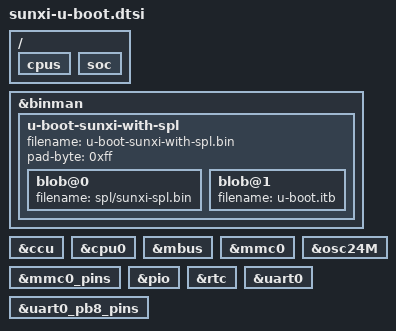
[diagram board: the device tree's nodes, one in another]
// SPDX-License-Identifier: (GPL-2.0 OR MIT)

#include "binman.dtsi"

/ {
	cpus {
		u-boot,dm-spl;
	};

	soc {
		u-boot,dm-spl;
	};
};

&binman {
	u-boot-sunxi-with-spl {
		filename = "u-boot-sunxi-with-spl.bin";
		pad-byte = <0xff>;

		blob@0 {
			filename = "spl/sunxi-spl.bin";
		};

		blob@1 {
			filename = "u-boot.itb";
		};
	};
};

&ccu {
	u-boot,dm-spl;
};

&cpu0 {
	u-boot,dm-spl;
};

&mbus {
	u-boot,dm-spl;
};

&mmc0 {
	u-boot,dm-spl;
};

&mmc0_pins {
	u-boot,dm-spl;
};

&osc24M {
	u-boot,dm-spl;
};

&pio {
	u-boot,dm-spl;
};

&rtc {
	u-boot,dm-spl;
};

&uart0 {
	u-boot,dm-spl;
};

&uart0_pb8_pins {
	u-boot,dm-spl;
};
